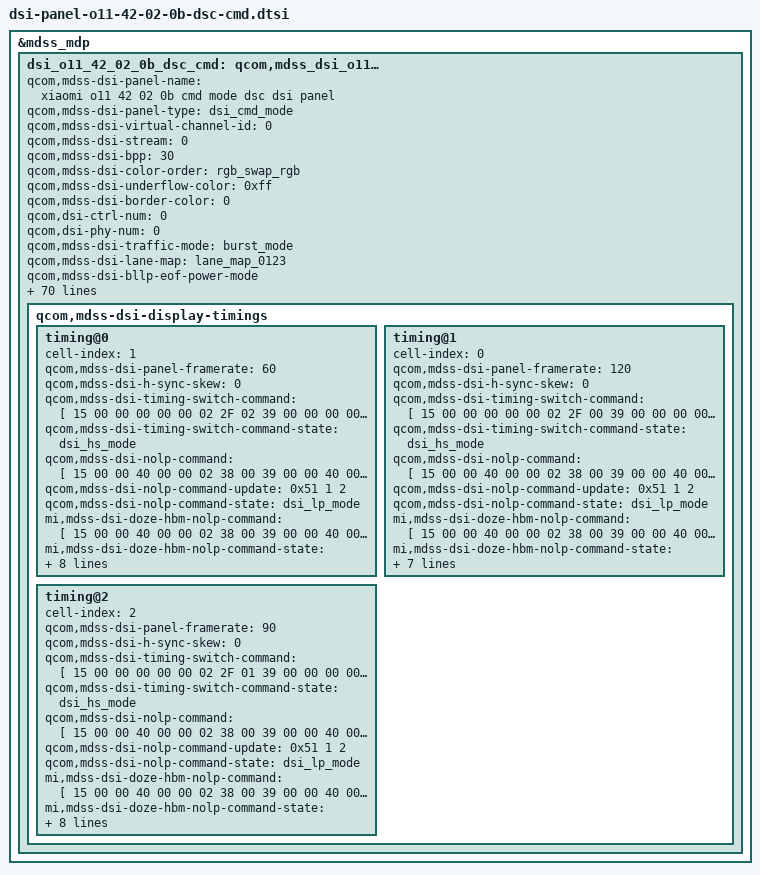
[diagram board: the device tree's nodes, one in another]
/* Panel Attention
 * 1.CCh must be 00 before 51h/26h/38h/39h/gamma change
 */
&mdss_mdp {
	dsi_o11_42_02_0b_dsc_cmd: qcom,mdss_dsi_o11_42_02_0b_dsc_cmd {
		qcom,mdss-dsi-panel-name = "xiaomi o11 42 02 0b cmd mode dsc dsi panel";
		qcom,mdss-dsi-panel-type = "dsi_cmd_mode";
		qcom,mdss-dsi-virtual-channel-id = <0>;
		qcom,mdss-dsi-stream = <0>;
		qcom,mdss-dsi-bpp = <30>;
		qcom,mdss-dsi-color-order = "rgb_swap_rgb";
		qcom,mdss-dsi-underflow-color = <0xff>;
		qcom,mdss-dsi-border-color = <0>;
		qcom,dsi-ctrl-num = <0>;
		qcom,dsi-phy-num = <0>;

		qcom,mdss-dsi-traffic-mode = "burst_mode";
		qcom,mdss-dsi-lane-map = "lane_map_0123";
		qcom,mdss-dsi-bllp-eof-power-mode;
		qcom,mdss-dsi-bllp-power-mode;
		qcom,mdss-dsi-lane-0-state;
		qcom,mdss-dsi-lane-1-state;
		qcom,mdss-dsi-lane-2-state;
		qcom,mdss-dsi-lane-3-state;
		qcom,mdss-dsi-dma-trigger = "trigger_sw";
		qcom,mdss-dsi-mdp-trigger = "none";
		qcom,mdss-dsi-reset-sequence = <1 11>, <0 1>, <1 11>;
		qcom,mdss-pan-physical-width-dimension = <695>;
		qcom,mdss-pan-physical-height-dimension = <1545>;
		qcom,mdss-dsi-te-pin-select = <1>;
		qcom,mdss-dsi-wr-mem-start = <0x2c>;
		qcom,mdss-dsi-wr-mem-continue = <0x3c>;
		qcom,mdss-dsi-te-dcs-command = <1>;
		qcom,mdss-dsi-te-check-enable;
		qcom,mdss-dsi-te-using-te-pin;
		qcom,mdss-dsi-tx-eot-append;
		qcom,mdss-dsi-lp11-init;

		qcom,mdss-dsi-bl-inverted-dbv;
		qcom,bl-update-flag = "delay_until_first_frame";

		qcom,mdss-dsi-panel-hdr-enabled;
		qcom,mdss-dsi-panel-hdr-color-primaries = <14500 15500 32000
			17000 15500 30000 8000 3000>;
		qcom,mdss-dsi-panel-peak-brightness = <32000000>;
		qcom,mdss-dsi-panel-blackness-level = <3230>;

		qcom,mdss-dsi-dma-schedule-line = <1>;
		qcom,mdss-dsi-dma-schedule-window = <50>;
		qcom,panel-supply-entries = <&dsi_panel_pwr_supply_o11>;


		qcom,spr-pack-type = "pentile";
		qcom,mdss-dsi-bl-pmic-control-type = "bl_ctrl_dcs";
		qcom,mdss-dsi-bl-min-level = <15>;
		qcom,mdss-dsi-bl-max-level = <16383>;
		qcom,bl-dsc-cmd-state = "dsi_hs_mode";
		qcom,mdss-brightness-max-level = <16383>;

		qcom,platform-reset-gpio = <&tlmm 133 0>;
		qcom,mdss-dsi-panel-vsync-delay;
		qcom,ulps-enabled;
		qcom,dsi-select-clocks = "pll_byte_clk0", "pll_dsi_clk0";
		qcom,mdss-dsi-clk-strength = <0xFF>;

		qcom,mdss-dsi-display-timings {
			/* 60 Hz */
			timing@0 {
				#include "dsi-panel-o11-42-02-0a-dsc-cmd-common.dtsi"
				cell-index = <1>;
				qcom,mdss-dsi-panel-framerate = <60>;
				qcom,mdss-dsi-h-sync-skew = <0>;
				qcom,mdss-dsi-timing-switch-command = [
					/* 60 Hz cmd_1 */
					15 00 00 00 00 00 02 2F 02
					/* EM 2pulse */
					39 00 00 00 00 00 06 F0 55 AA 52 08 00
					15 00 00 00 00 00 02 6F CC
					15 00 00 00 00 00 02 B2 01
				];
				qcom,mdss-dsi-timing-switch-command-state = "dsi_hs_mode";

				qcom,mdss-dsi-nolp-command = [
					/* AOD Mode off */
					15 00 00 40 00 00 02 38 00
					39 00 00 40 00 00 03 51 00 00
					/* 60 Hz cmd_1 */
					15 00 00 40 00 00 02 2F 02
					/* EM 2pulse */
					39 00 00 40 00 00 06 F0 55 AA 52 08 00
					15 00 00 40 00 00 02 6F CC
					15 00 00 40 00 00 02 B2 01
					/* ERR Flag enable */
					39 00 00 40 00 00 06 F0 55 AA 52 08 00
					39 00 00 40 00 00 03 BE 47 45
					15 00 00 40 00 00 02 6F 05
					15 00 00 00 00 00 02 BE 08
				];
				qcom,mdss-dsi-nolp-command-update = <0x51 1 2>;
				qcom,mdss-dsi-nolp-command-state = "dsi_lp_mode";

				mi,mdss-dsi-doze-hbm-nolp-command = [
					/* AOD Mode off */
					15 00 00 40 00 00 02 38 00
					39 00 00 40 00 00 03 51 01 9C
					/* 60 Hz cmd_1 */
					15 00 00 40 00 00 02 2F 02
					/* EM 2pulse */
					39 00 00 40 00 00 06 F0 55 AA 52 08 00
					15 00 00 40 00 00 02 6F CC
					15 00 00 40 00 00 02 B2 01
					/* ERR Flag enable */
					39 00 00 40 00 00 06 F0 55 AA 52 08 00
					39 00 00 40 00 00 03 BE 47 45
					15 00 00 40 00 00 02 6F 05
					15 00 00 00 00 00 02 BE 08
				];
				mi,mdss-dsi-doze-hbm-nolp-command-state = "dsi_lp_mode";

				mi,mdss-dsi-doze-lbm-nolp-command = [
					/* AOD Mode off */
					15 00 00 40 00 00 02 38 00
					39 00 00 40 00 00 03 51 00 23
					/* 60 Hz cmd_1 */
					15 00 00 40 00 00 02 2F 02
					/* EM 2pulse */
					39 00 00 40 00 00 06 F0 55 AA 52 08 00
					15 00 00 40 00 00 02 6F CC
					15 00 00 40 00 00 02 B2 01
					/* ERR Flag enable */
					39 00 00 40 00 00 06 F0 55 AA 52 08 00
					39 00 00 40 00 00 03 BE 47 45
					15 00 00 40 00 00 02 6F 05
					15 00 00 00 00 00 02 BE 08
				];
				mi,mdss-dsi-doze-lbm-nolp-command-state = "dsi_lp_mode";

				qcom,mdss-dsi-on-command = [
					/* 1440 */
					39 00 00 00 00 00 05 2A 00 00 05 9F
					/* 3200 */
					39 00 00 00 00 00 05 2B 00 00 0C 7F
					/* VESA Setting (DSCv1.2  2DEC  slice height=20) */
					39 00 00 00 00 00 03 90 03 43
					39 00 00 00 00 00 13 91 AB F0 00 14 D1 00 01 DE 00 A3 00 3C 05 7A 15 9A 11 50	//AP SPR
					39 00 00 00 00 00 06 F0 55 AA 52 08 03
					15 00 00 00 00 00 02 6F 09
					39 00 00 00 00 00 07 DE 10 34 25 30 14 25
					39 00 00 00 00 00 06 F0 55 AA 52 08 07
					39 00 00 00 00 00 06 B0 84 44 01 00 40
					/* 60 Hz cmd_1 */
					15 00 00 00 00 00 02 2F 02
					/* EM 2pulse */
					39 00 00 00 00 00 06 F0 55 AA 52 08 00
					15 00 00 00 00 00 02 6F CC
					15 00 00 00 00 00 02 B2 01
					39 00 00 00 00 00 03 51 00 00
					/* idle_dbv */
					15 00 00 00 00 00 02 6F 04
					39 00 00 00 00 00 03 51 0F FF
					/* BCTRL=1 */
					15 00 00 00 00 00 02 53 20
					15 00 00 00 00 00 02 35 00
					15 00 00 00 00 00 02 6F 01
					/* DC_MODE=1 */
					15 00 00 00 00 00 02 8B 00
					/* BCC OFF */
					39 00 00 00 00 00 06 F0 55 AA 52 08 08
					15 00 00 00 00 00 02 B3 00
					/* AOD pulse */
					39 00 00 00 00 00 06 F0 55 AA 52 08 01
					15 00 00 00 00 00 02 6F A2
					39 00 00 00 00 00 06 E7 FF FF FF FF FF
					15 00 00 00 00 00 02 6F 11
					15 00 00 00 00 00 02 E7 08
					/* Show Demura */
					39 00 00 00 00 00 06 F0 55 AA 52 08 00
					15 00 00 00 00 00 02 C7 33
					15 00 00 00 00 00 02 6F 31
					39 00 00 00 00 00 03 C0 00 10
					15 00 00 00 00 00 02 6F 35
					39 00 00 00 00 00 03 C0 22 40
					39 00 00 00 00 00 06 F0 55 AA 52 08 04
					15 00 00 00 00 00 02 C0 20
					/* Demura ON */
					39 00 00 40 00 00 06 F0 55 AA 52 08 04
					15 00 00 00 00 00 02 CA 01
					/* OD ON*/
					39 00 00 00 00 00 06 F0 55 AA 52 08 08
					39 00 00 00 00 00 07 E8 11 80 00 00 00 20
					15 00 00 00 00 00 02 6F 06
					39 00 00 00 00 00 18 E8 00 78 7C 7C 80 80 84 84 88 88 9C 9C 80 80 7C 7C 78 78 74 74 68 68 68
					15 00 00 00 00 00 02 6F 1D
					39 00 00 00 00 00 18 E8 00 88 90 90 94 94 9C 9C A0 A0 B8 B8 90 90 8C 8C 88 88 84 84 74 74 74
					15 00 00 00 00 00 02 6F 34
					39 00 00 00 00 00 18 E8 00 E8 E8 E8 E8 E8 E8 E8 E8 E8 F0 F0 AC AC AC AC A8 A8 A8 A8 90 90 90
					39 00 00 00 00 00 06 F0 55 AA 52 08 08
					39 00 00 00 00 00 05 E0 01 01 01 01
					15 00 00 00 00 00 02 6F 06
					39 00 00 00 00 00 0E E0 80 00 21 32 43 54 65 76 87 98 99 99 99
					39 00 00 00 00 00 33 E1 00 00 00 00 00 00 01 01 01 02 02 03 03 05 00 00 00 00 00 00 00 00 00 03 03 05 08 0A 00 00 00 00 00 00 01 01 02 04 04 05 08 0A 00 00 00 00 00 00 00 00
					15 00 00 00 00 00 02 6F 32
					39 00 00 00 00 00 33 E1 03 04 06 07 0B 0C 00 00 00 00 00 00 01 01 04 07 09 0A 0C 0E 00 00 01 01 02 02 02 03 04 06 07 09 0A 0B 00 00 01 01 02 02 02 03 06 07 09 0A 0C 0D 00 00
					15 00 00 00 00 00 02 6F 64
					39 00 00 00 00 00 1B E1 00 00 00 01 02 02 03 05 08 0C 0D 0E 00 00 00 00 01 02 02 03 05 06 09 0B 0F 11
					39 00 00 00 00 00 33 E2 01 02 02 03 04 04 04 05 0A 0A 0E 14 1A 1A 00 00 00 00 01 02 03 04 06 06 0C 10 12 11 00 00 00 00 02 04 06 08 0A 0A 0A 0E 10 11 00 00 00 00 02 04 05 07
					15 00 00 00 00 00 02 6F 32
					39 00 00 00 00 00 33 E2 07 09 0B 0C 0F 12 00 00 00 00 02 04 05 07 07 08 0B 0D 10 11 00 00 00 00 02 03 04 06 06 08 0A 0C 0D 0F 00 00 00 00 01 02 04 05 07 09 0B 0C 0F 11 00 01
					15 00 00 00 00 00 02 6F 64
					39 00 00 00 00 00 1B E2 02 02 02 03 04 04 07 08 09 0D 0E 12 00 00 00 00 01 02 03 04 06 08 09 0B 10 12
					39 00 00 00 00 00 33 E3 00 00 00 00 00 00 00 00 00 00 06 07 08 0A 00 00 00 00 00 00 00 00 00 00 05 0A 0F 0F 00 00 00 00 00 00 00 00 00 04 04 06 0E 10 00 00 00 00 00 01 02 02
					15 00 00 00 00 00 02 6F 32
					39 00 00 00 00 00 33 E3 02 06 08 0C 0D 0F 00 00 00 00 00 01 02 02 05 06 0A 0B 0E 11 00 00 00 00 01 02 03 04 04 07 08 0A 0D 0F 00 00 00 00 01 02 02 03 06 08 09 0B 0E 11 00 00
					15 00 00 00 00 00 02 6F 64
					39 00 00 00 00 00 1B E3 01 01 02 02 03 04 05 07 0A 0C 0F 11 00 00 00 00 01 02 02 03 06 07 0A 0D 0F 12
					39 00 00 00 00 00 1C EA 00 00 00 00 00 00 00 00 00 00 00 00 00 00 00 00 00 00 00 00 00 00 00 00 00 00 00
					39 00 00 00 00 00 0A E4 00 00 00 00 00 00 00 00 00
					39 00 00 00 00 00 0A E5 00 00 00 00 00 00 00 00 00
					39 00 00 00 00 00 0A E6 00 00 00 00 00 00 00 00 00
					39 00 00 40 00 00 06 F0 55 AA 52 08 08
					15 00 00 40 00 00 02 E8 11
					15 00 00 00 00 00 02 E0 01
					/* DBV Remapping */
					39 00 00 00 00 00 06 F0 55 AA 52 08 09
					15 00 00 00 00 00 02 BC 01
					15 00 00 00 00 00 02 6F 25
					39 00 00 00 00 00 13 BC 01 9B 01 9B 01 9B 04 18 05 AC 06 F7 09 FF 0B FF 0D FF
					15 00 00 00 00 00 02 6F 37
					39 00 00 00 00 00 13 BC 11 54 12 A9 13 FE 1D EF 24 9F 2A B9 33 FD 37 FE 3B FE
					15 00 00 00 00 00 02 6F 49
					39 00 00 00 00 00 13 BC 01 9B 01 9B 01 9B 04 18 05 AC 06 F7 09 FF 0B FF 0D FF
					15 00 00 00 00 00 02 6F 5B
					39 00 00 00 00 00 13 BC 11 54 12 A9 13 FE 1D EF 24 9F 2A B9 33 FD 37 FE 3B FE
					/* ESD ERR Flag */
					39 00 00 00 00 00 06 F0 55 AA 52 08 00
					39 00 00 00 00 00 03 BE 47 45
					15 00 00 00 00 00 02 6F 05
					15 00 00 00 00 00 02 BE 08
					39 00 00 00 00 00 06 F0 55 AA 52 08 00
					15 00 00 00 00 00 02 6F 18
					15 00 00 00 00 00 02 B2 41
					/*  ESD error config */
					39 00 00 00 00 00 06 F0 55 AA 52 08 03
					39 00 00 00 00 00 04 C8 01 FF FB
					39 00 00 00 00 00 05 FF AA 55 A5 80
					15 00 00 00 00 00 02 6F 22
					15 00 00 00 00 00 02 FE 06
					/* APL Data scaling */
					39 00 00 00 00 00 06 F0 55 AA 52 08 00
					15 00 00 00 00 00 02 6F 78
					39 00 00 00 00 00 18 B0 11 00 2A 00 C2 01 DA 03 7C 05 B1 08 80 0B EE 0F FF 05 55 05 56 05 55
					15 00 00 00 00 00 02 6F 6F
					39 00 00 00 00 00 07 B0 02 D0 05 A0 02 D0
					39 00 00 00 00 00 06 F0 55 AA 52 08 08
					39 00 00 00 00 00 17 C1 8C FF CC FF FF CC FF FF CC FF FF EC FF 7F EE 7F 7F FF 7F FF 0E 7F
					15 00 00 00 00 00 02 6F 20
					39 00 00 00 00 00 04 C1 4F 00 FF
					15 00 00 00 00 00 02 6F 23
					39 00 00 00 00 00 15 C1 0C FF CC FF FF CC FF FF CC FF FF EC FF 7F EE 7F 7F CF 7F 0A
					/* Round ON */
					39 00 00 00 00 00 06 F0 55 AA 52 08 07
					15 00 00 00 00 00 02 C0 87
					/* OSC_Trim_On */
					39 00 00 00 00 00 06 F0 55 AA 52 08 01
					15 00 00 00 00 00 02 6F 2F
					15 00 00 00 00 00 02 C3 77
					/* OSC=125.2MHz, 1200Mbps */
					15 00 00 00 00 00 02 6F 00
					15 00 00 00 00 00 02 C3 DD
					15 00 00 00 00 00 02 6F 30
					15 00 00 00 00 00 02 C3 C0
					15 00 00 00 00 00 02 6F 0B
					39 00 00 00 00 00 04 C3 3F 3A 2F
					15 00 00 00 00 00 02 6F 11
					39 00 00 00 00 00 04 C3 3F 3A 2F
					15 00 00 00 00 00 02 6F 17
					39 00 00 00 00 00 04 C3 3F 3A 2F
					15 00 00 00 00 00 02 6F 1D
					39 00 00 00 00 00 04 C3 3F 3A 2F
					15 00 00 00 00 00 02 6F 23
					39 00 00 00 00 00 04 C3 3F 3A 2F
					15 00 00 00 00 00 02 6F 0E
					39 00 00 00 00 00 04 C3 3F 62 DE
					15 00 00 00 00 00 02 6F 14
					39 00 00 00 00 00 04 C3 3F 62 DE
					15 00 00 00 00 00 02 6F 1A
					39 00 00 00 00 00 04 C3 3F 62 DE
					15 00 00 00 00 00 02 6F 20
					39 00 00 00 00 00 04 C3 3F 62 DE
					15 00 00 00 00 00 02 6F 26
					39 00 00 00 00 00 04 C3 3F 62 DE
					15 00 00 00 00 00 02 6F 29
					39 00 00 00 00 00 04 C3 11 11 01
					15 00 00 00 00 00 02 6F 2C
					39 00 00 00 00 00 04 C3 00 00 00
					15 00 00 00 00 00 02 6F 31
					39 00 00 00 00 00 03 C3 AA 02
					15 00 00 00 00 00 02 6F 33
					39 00 00 00 00 00 03 C3 AA 02
					15 00 00 00 00 00 02 6F 04
					15 00 00 00 00 00 02 C3 E3
					15 00 00 00 00 00 02 6F 09
					15 00 00 00 00 00 02 C3 E4
					15 00 00 00 00 00 02 6F 01
					15 00 00 00 00 00 02 C3 29
					15 00 00 00 00 00 02 6F 06
					15 00 00 00 00 00 02 C3 29
					15 00 00 00 00 00 02 6F 02
					39 00 00 00 00 00 03 C3 02 70
					15 00 00 00 00 00 02 6F 08
					15 00 00 00 00 00 02 C3 70
					39 00 00 00 00 00 06 F0 55 AA 52 08 01
					15 00 00 00 00 00 02 EA 11
					15 00 00 00 00 00 02 6F 07
					39 00 00 00 00 00 03 EA 01 39
					15 00 00 00 00 00 02 6F 0B
					15 00 00 00 00 00 02 EA 11
					15 00 00 00 00 00 02 6F 12
					39 00 00 00 00 00 03 EA 01 AC
					15 00 00 00 00 00 02 6F 1A
					39 00 00 00 00 00 03 EA 01 39
					15 00 00 00 00 00 02 6F 1C
					39 00 00 00 00 00 03 EA 01 AC
					15 00 00 00 00 00 02 6F 04
					15 00 00 00 00 00 02 C3 EA
					15 00 00 00 00 00 02 6F 09
					15 00 00 00 00 00 02 C3 EA
					/* Sleep Out */
					05 00 00 00 78 00 02 11 00
					/* Display On */
					05 00 00 00 00 00 02 29 00
				];
				qcom,mdss-dsi-on-command-state = "dsi_lp_mode";
			};

			/* 120 Hz */
			timing@1 {
				#include "dsi-panel-o11-42-02-0a-dsc-cmd-common.dtsi"
				cell-index = <0>;
				qcom,mdss-dsi-panel-framerate = <120>;
				qcom,mdss-dsi-h-sync-skew = <0>;
				qcom,mdss-dsi-timing-switch-command = [
					/* 120 Hz cmd_1 */
					15 00 00 00 00 00 02 2F 00
					/* EM 1pulse */
					39 00 00 00 00 00 06 F0 55 AA 52 08 00
					15 00 00 00 00 00 02 6F CC
					15 00 00 00 00 00 02 B2 00
				];
				qcom,mdss-dsi-timing-switch-command-state = "dsi_hs_mode";

				qcom,mdss-dsi-nolp-command = [
					/* AOD Mode off */
					15 00 00 40 00 00 02 38 00
					39 00 00 40 00 00 03 51 00 00
					/* 120 Hz cmd_1 */
					15 00 00 40 00 00 02 2F 00
					/* EM 1pulse */
					39 00 00 40 00 00 06 F0 55 AA 52 08 00
					15 00 00 40 00 00 02 6F CC
					15 00 00 40 00 00 02 B2 00
					/* ERR Flag enable */
					39 00 00 40 00 00 06 F0 55 AA 52 08 00
					39 00 00 40 00 00 03 BE 47 45
					15 00 00 40 00 00 02 6F 05
					15 00 00 00 00 00 02 BE 08
				];
				qcom,mdss-dsi-nolp-command-update = <0x51 1 2>;
				qcom,mdss-dsi-nolp-command-state = "dsi_lp_mode";

				mi,mdss-dsi-doze-hbm-nolp-command = [
					/* AOD Mode off */
					15 00 00 40 00 00 02 38 00
					39 00 00 40 00 00 03 51 01 9C
					/* 120 Hz cmd_1 */
					15 00 00 40 00 00 02 2F 00
					/* EM 1pulse */
					39 00 00 40 00 00 06 F0 55 AA 52 08 00
					15 00 00 40 00 00 02 6F CC
					15 00 00 40 00 00 02 B2 00
					/* ERR Flag enable */
					39 00 00 40 00 00 06 F0 55 AA 52 08 00
					39 00 00 40 00 00 03 BE 47 45
					15 00 00 40 00 00 02 6F 05
					15 00 00 00 00 00 02 BE 08
				];
				mi,mdss-dsi-doze-hbm-nolp-command-state = "dsi_lp_mode";

				mi,mdss-dsi-doze-lbm-nolp-command = [
					/* AOD Mode off */
					15 00 00 40 00 00 02 38 00
					39 00 00 40 00 00 03 51 00 23
					/* 120 Hz cmd_1 */
					15 00 00 40 00 00 02 2F 00
					/* EM 1pulse */
					39 00 00 40 00 00 06 F0 55 AA 52 08 00
					15 00 00 40 00 00 02 6F CC
					15 00 00 40 00 00 02 B2 00
					/* ERR Flag enable */
					39 00 00 40 00 00 06 F0 55 AA 52 08 00
					39 00 00 40 00 00 03 BE 47 45
					15 00 00 40 00 00 02 6F 05
					15 00 00 00 00 00 02 BE 08
				];
				mi,mdss-dsi-doze-lbm-nolp-command-state = "dsi_lp_mode";

				qcom,mdss-dsi-on-command = [
					/* 1440 */
					39 00 00 00 00 00 05 2A 00 00 05 9F
					/* 3200 */
					39 00 00 00 00 00 05 2B 00 00 0C 7F
					/* VESA Setting (DSCv1.2  2DEC  slice height=20) */
					39 00 00 00 00 00 03 90 03 43
					39 00 00 00 00 00 13 91 AB F0 00 14 D1 00 01 DE 00 A3 00 3C 05 7A 15 9A 11 50	//AP SPR
					39 00 00 00 00 00 06 F0 55 AA 52 08 03
					15 00 00 00 00 00 02 6F 09
					39 00 00 00 00 00 07 DE 10 34 25 30 14 25
					39 00 00 00 00 00 06 F0 55 AA 52 08 07
					39 00 00 00 00 00 06 B0 84 44 01 00 40
					/* 120 Hz cmd_1 */
					15 00 00 00 00 00 02 2F 00
					/* EM 1pulse */
					39 00 00 00 00 00 06 F0 55 AA 52 08 00
					15 00 00 00 00 00 02 6F CC
					15 00 00 00 00 00 02 B2 00
					39 00 00 00 00 00 03 51 00 00
					/* idle_dbv */
					15 00 00 00 00 00 02 6F 04
					39 00 00 00 00 00 03 51 0F FF
					/* BCTRL=1 */
					15 00 00 00 00 00 02 53 20
					15 00 00 00 00 00 02 35 00
					15 00 00 00 00 00 02 6F 01
					/* DC_MODE=1 */
					15 00 00 00 00 00 02 8B 00
					/* BCC OFF */
					39 00 00 00 00 00 06 F0 55 AA 52 08 08
					15 00 00 00 00 00 02 B3 00
					/* AOD pulse */
					39 00 00 00 00 00 06 F0 55 AA 52 08 01
					15 00 00 00 00 00 02 6F A2
					39 00 00 00 00 00 06 E7 FF FF FF FF FF
					15 00 00 00 00 00 02 6F 11
					15 00 00 00 00 00 02 E7 08
					/* Show Demura */
					39 00 00 00 00 00 06 F0 55 AA 52 08 00
					15 00 00 00 00 00 02 C7 33
					15 00 00 00 00 00 02 6F 31
					39 00 00 00 00 00 03 C0 00 10
					15 00 00 00 00 00 02 6F 35
					39 00 00 00 00 00 03 C0 22 40
					39 00 00 00 00 00 06 F0 55 AA 52 08 04
					15 00 00 00 00 00 02 C0 20
					/* Demura ON */
					39 00 00 40 00 00 06 F0 55 AA 52 08 04
					15 00 00 00 00 00 02 CA 01
					/* OD ON*/
					39 00 00 00 00 00 06 F0 55 AA 52 08 08
					39 00 00 00 00 00 07 E8 11 80 00 00 00 20
					15 00 00 00 00 00 02 6F 06
					39 00 00 00 00 00 18 E8 00 78 7C 7C 80 80 84 84 88 88 9C 9C 80 80 7C 7C 78 78 74 74 68 68 68
					15 00 00 00 00 00 02 6F 1D
					39 00 00 00 00 00 18 E8 00 88 90 90 94 94 9C 9C A0 A0 B8 B8 90 90 8C 8C 88 88 84 84 74 74 74
					15 00 00 00 00 00 02 6F 34
					39 00 00 00 00 00 18 E8 00 E8 E8 E8 E8 E8 E8 E8 E8 E8 F0 F0 AC AC AC AC A8 A8 A8 A8 90 90 90
					39 00 00 00 00 00 06 F0 55 AA 52 08 08
					39 00 00 00 00 00 05 E0 01 01 01 01
					15 00 00 00 00 00 02 6F 06
					39 00 00 00 00 00 0E E0 80 00 21 32 43 54 65 76 87 98 99 99 99
					39 00 00 00 00 00 33 E1 00 00 00 00 00 00 01 01 01 02 02 03 03 05 00 00 00 00 00 00 00 00 00 03 03 05 08 0A 00 00 00 00 00 00 01 01 02 04 04 05 08 0A 00 00 00 00 00 00 00 00
					15 00 00 00 00 00 02 6F 32
					39 00 00 00 00 00 33 E1 03 04 06 07 0B 0C 00 00 00 00 00 00 01 01 04 07 09 0A 0C 0E 00 00 01 01 02 02 02 03 04 06 07 09 0A 0B 00 00 01 01 02 02 02 03 06 07 09 0A 0C 0D 00 00
					15 00 00 00 00 00 02 6F 64
					39 00 00 00 00 00 1B E1 00 00 00 01 02 02 03 05 08 0C 0D 0E 00 00 00 00 01 02 02 03 05 06 09 0B 0F 11
					39 00 00 00 00 00 33 E2 01 02 02 03 04 04 04 05 0A 0A 0E 14 1A 1A 00 00 00 00 01 02 03 04 06 06 0C 10 12 11 00 00 00 00 02 04 06 08 0A 0A 0A 0E 10 11 00 00 00 00 02 04 05 07
					15 00 00 00 00 00 02 6F 32
					39 00 00 00 00 00 33 E2 07 09 0B 0C 0F 12 00 00 00 00 02 04 05 07 07 08 0B 0D 10 11 00 00 00 00 02 03 04 06 06 08 0A 0C 0D 0F 00 00 00 00 01 02 04 05 07 09 0B 0C 0F 11 00 01
					15 00 00 00 00 00 02 6F 64
					39 00 00 00 00 00 1B E2 02 02 02 03 04 04 07 08 09 0D 0E 12 00 00 00 00 01 02 03 04 06 08 09 0B 10 12
					39 00 00 00 00 00 33 E3 00 00 00 00 00 00 00 00 00 00 06 07 08 0A 00 00 00 00 00 00 00 00 00 00 05 0A 0F 0F 00 00 00 00 00 00 00 00 00 04 04 06 0E 10 00 00 00 00 00 01 02 02
					15 00 00 00 00 00 02 6F 32
					39 00 00 00 00 00 33 E3 02 06 08 0C 0D 0F 00 00 00 00 00 01 02 02 05 06 0A 0B 0E 11 00 00 00 00 01 02 03 04 04 07 08 0A 0D 0F 00 00 00 00 01 02 02 03 06 08 09 0B 0E 11 00 00
					15 00 00 00 00 00 02 6F 64
					39 00 00 00 00 00 1B E3 01 01 02 02 03 04 05 07 0A 0C 0F 11 00 00 00 00 01 02 02 03 06 07 0A 0D 0F 12
					39 00 00 00 00 00 1C EA 00 00 00 00 00 00 00 00 00 00 00 00 00 00 00 00 00 00 00 00 00 00 00 00 00 00 00
					39 00 00 00 00 00 0A E4 00 00 00 00 00 00 00 00 00
					39 00 00 00 00 00 0A E5 00 00 00 00 00 00 00 00 00
					39 00 00 00 00 00 0A E6 00 00 00 00 00 00 00 00 00
					39 00 00 40 00 00 06 F0 55 AA 52 08 08
					15 00 00 40 00 00 02 E8 11
					15 00 00 00 00 00 02 E0 01
					/* DBV Remapping */
					39 00 00 00 00 00 06 F0 55 AA 52 08 09
					15 00 00 00 00 00 02 BC 01
					15 00 00 00 00 00 02 6F 25
					39 00 00 00 00 00 13 BC 01 9B 01 9B 01 9B 04 18 05 AC 06 F7 09 FF 0B FF 0D FF
					15 00 00 00 00 00 02 6F 37
					39 00 00 00 00 00 13 BC 11 54 12 A9 13 FE 1D EF 24 9F 2A B9 33 FD 37 FE 3B FE
					15 00 00 00 00 00 02 6F 49
					39 00 00 00 00 00 13 BC 01 9B 01 9B 01 9B 04 18 05 AC 06 F7 09 FF 0B FF 0D FF
					15 00 00 00 00 00 02 6F 5B
					39 00 00 00 00 00 13 BC 11 54 12 A9 13 FE 1D EF 24 9F 2A B9 33 FD 37 FE 3B FE
					/* ESD ERR Flag */
					39 00 00 00 00 00 06 F0 55 AA 52 08 00
					39 00 00 00 00 00 03 BE 47 45
					15 00 00 00 00 00 02 6F 05
					15 00 00 00 00 00 02 BE 08
					39 00 00 00 00 00 06 F0 55 AA 52 08 00
					15 00 00 00 00 00 02 6F 18
					15 00 00 00 00 00 02 B2 41
					/*  ESD error config */
					39 00 00 00 00 00 06 F0 55 AA 52 08 03
					39 00 00 00 00 00 04 C8 01 FF FB
					39 00 00 00 00 00 05 FF AA 55 A5 80
					15 00 00 00 00 00 02 6F 22
					15 00 00 00 00 00 02 FE 06
					/* APL Data scaling */
					39 00 00 00 00 00 06 F0 55 AA 52 08 00
					15 00 00 00 00 00 02 6F 78
					39 00 00 00 00 00 18 B0 11 00 2A 00 C2 01 DA 03 7C 05 B1 08 80 0B EE 0F FF 05 55 05 56 05 55
					15 00 00 00 00 00 02 6F 6F
					39 00 00 00 00 00 07 B0 02 D0 05 A0 02 D0
					39 00 00 00 00 00 06 F0 55 AA 52 08 08
					39 00 00 00 00 00 17 C1 8C FF CC FF FF CC FF FF CC FF FF EC FF 7F EE 7F 7F FF 7F FF 0E 7F
					15 00 00 00 00 00 02 6F 20
					39 00 00 00 00 00 04 C1 4F 00 FF
					15 00 00 00 00 00 02 6F 23
					39 00 00 00 00 00 15 C1 0C FF CC FF FF CC FF FF CC FF FF EC FF 7F EE 7F 7F CF 7F 0A
					/* Round ON */
					39 00 00 00 00 00 06 F0 55 AA 52 08 07
					15 00 00 00 00 00 02 C0 87
					/* OSC_Trim_On */
					39 00 00 00 00 00 06 F0 55 AA 52 08 01
					15 00 00 00 00 00 02 6F 2F
					15 00 00 00 00 00 02 C3 77
					/* OSC=125.2MHz, 1200Mbps */
					15 00 00 00 00 00 02 6F 00
					15 00 00 00 00 00 02 C3 DD
					15 00 00 00 00 00 02 6F 30
					15 00 00 00 00 00 02 C3 C0
					15 00 00 00 00 00 02 6F 0B
					39 00 00 00 00 00 04 C3 3F 3A 2F
					15 00 00 00 00 00 02 6F 11
					39 00 00 00 00 00 04 C3 3F 3A 2F
					15 00 00 00 00 00 02 6F 17
					39 00 00 00 00 00 04 C3 3F 3A 2F
					15 00 00 00 00 00 02 6F 1D
					39 00 00 00 00 00 04 C3 3F 3A 2F
					15 00 00 00 00 00 02 6F 23
					39 00 00 00 00 00 04 C3 3F 3A 2F
					15 00 00 00 00 00 02 6F 0E
					39 00 00 00 00 00 04 C3 3F 62 DE
					15 00 00 00 00 00 02 6F 14
					39 00 00 00 00 00 04 C3 3F 62 DE
					15 00 00 00 00 00 02 6F 1A
					39 00 00 00 00 00 04 C3 3F 62 DE
					15 00 00 00 00 00 02 6F 20
					39 00 00 00 00 00 04 C3 3F 62 DE
					15 00 00 00 00 00 02 6F 26
					39 00 00 00 00 00 04 C3 3F 62 DE
					15 00 00 00 00 00 02 6F 29
					39 00 00 00 00 00 04 C3 11 11 01
					15 00 00 00 00 00 02 6F 2C
					39 00 00 00 00 00 04 C3 00 00 00
					15 00 00 00 00 00 02 6F 31
					39 00 00 00 00 00 03 C3 AA 02
					15 00 00 00 00 00 02 6F 33
					39 00 00 00 00 00 03 C3 AA 02
					15 00 00 00 00 00 02 6F 04
					15 00 00 00 00 00 02 C3 E3
					15 00 00 00 00 00 02 6F 09
					15 00 00 00 00 00 02 C3 E4
					15 00 00 00 00 00 02 6F 01
					15 00 00 00 00 00 02 C3 29
					15 00 00 00 00 00 02 6F 06
					15 00 00 00 00 00 02 C3 29
					15 00 00 00 00 00 02 6F 02
					39 00 00 00 00 00 03 C3 02 70
					15 00 00 00 00 00 02 6F 08
					15 00 00 00 00 00 02 C3 70
					39 00 00 00 00 00 06 F0 55 AA 52 08 01
					15 00 00 00 00 00 02 EA 11
					15 00 00 00 00 00 02 6F 07
					39 00 00 00 00 00 03 EA 01 39
					15 00 00 00 00 00 02 6F 0B
					15 00 00 00 00 00 02 EA 11
					15 00 00 00 00 00 02 6F 12
					39 00 00 00 00 00 03 EA 01 AC
					15 00 00 00 00 00 02 6F 1A
					39 00 00 00 00 00 03 EA 01 39
					15 00 00 00 00 00 02 6F 1C
					39 00 00 00 00 00 03 EA 01 AC
					15 00 00 00 00 00 02 6F 04
					15 00 00 00 00 00 02 C3 EA
					15 00 00 00 00 00 02 6F 09
					15 00 00 00 00 00 02 C3 EA
					/* Sleep Out */
					05 00 00 00 78 00 02 11 00
					/* Display On */
					05 00 00 00 00 00 02 29 00
				];
			};

			/* 90 Hz */
			timing@2 {
				#include "dsi-panel-o11-42-02-0a-dsc-cmd-common.dtsi"
				cell-index = <2>;
				qcom,mdss-dsi-panel-framerate = <90>;
				qcom,mdss-dsi-h-sync-skew = <0>;
				qcom,mdss-dsi-timing-switch-command = [
					/* 90 Hz cmd_1 */
					15 00 00 00 00 00 02 2F 01
					/* EM 1pulse */
					39 00 00 00 00 00 06 F0 55 AA 52 08 00
					15 00 00 00 00 00 02 6F CC
					15 00 00 00 00 00 02 B2 00
				];
				qcom,mdss-dsi-timing-switch-command-state = "dsi_hs_mode";

				qcom,mdss-dsi-nolp-command = [
					/* AOD Mode off */
					15 00 00 40 00 00 02 38 00
					39 00 00 40 00 00 03 51 00 00
					/* 90 Hz cmd_1 */
					15 00 00 40 00 00 02 2F 01
					/* EM 1pulse */
					39 00 00 40 00 00 06 F0 55 AA 52 08 00
					15 00 00 40 00 00 02 6F CC
					15 00 00 40 00 00 02 B2 00
					/* ERR Flag enable */
					39 00 00 40 00 00 06 F0 55 AA 52 08 00
					39 00 00 40 00 00 03 BE 47 45
					15 00 00 40 00 00 02 6F 05
					15 00 00 00 00 00 02 BE 08
				];
				qcom,mdss-dsi-nolp-command-update = <0x51 1 2>;
				qcom,mdss-dsi-nolp-command-state = "dsi_lp_mode";

				mi,mdss-dsi-doze-hbm-nolp-command = [
					/* AOD Mode off */
					15 00 00 40 00 00 02 38 00
					39 00 00 40 00 00 03 51 01 9C
					/* 90 Hz cmd_1 */
					15 00 00 40 00 00 02 2F 01
					/* EM 1pulse */
					39 00 00 40 00 00 06 F0 55 AA 52 08 00
					15 00 00 40 00 00 02 6F CC
					15 00 00 40 00 00 02 B2 00
					/* ERR Flag enable */
					39 00 00 40 00 00 06 F0 55 AA 52 08 00
					39 00 00 40 00 00 03 BE 47 45
					15 00 00 40 00 00 02 6F 05
					15 00 00 00 00 00 02 BE 08
				];
				mi,mdss-dsi-doze-hbm-nolp-command-state = "dsi_lp_mode";

				mi,mdss-dsi-doze-lbm-nolp-command = [
					/* AOD Mode off */
					15 00 00 40 00 00 02 38 00
					39 00 00 40 00 00 03 51 00 23
					/* 90 Hz cmd_1 */
					15 00 00 40 00 00 02 2F 01
					/* EM 1pulse */
					39 00 00 40 00 00 06 F0 55 AA 52 08 00
					15 00 00 40 00 00 02 6F CC
					15 00 00 40 00 00 02 B2 00
					/* ERR Flag enable */
					39 00 00 40 00 00 06 F0 55 AA 52 08 00
					39 00 00 40 00 00 03 BE 47 45
					15 00 00 40 00 00 02 6F 05
					15 00 00 00 00 00 02 BE 08
				];
				mi,mdss-dsi-doze-lbm-nolp-command-state = "dsi_lp_mode";

				qcom,mdss-dsi-on-command = [
					/* 1440 */
					39 00 00 00 00 00 05 2A 00 00 05 9F
					/* 3200 */
					39 00 00 00 00 00 05 2B 00 00 0C 7F
					/* VESA Setting (DSCv1.2  2DEC  slice height=20) */
					39 00 00 00 00 00 03 90 03 43
					39 00 00 00 00 00 13 91 AB F0 00 14 D1 00 01 DE 00 A3 00 3C 05 7A 15 9A 11 50	//AP SPR
					39 00 00 00 00 00 06 F0 55 AA 52 08 03
					15 00 00 00 00 00 02 6F 09
					39 00 00 00 00 00 07 DE 10 34 25 30 14 25
					39 00 00 00 00 00 06 F0 55 AA 52 08 07
					39 00 00 00 00 00 06 B0 84 44 01 00 40
					/* 90 Hz cmd_1 */
					15 00 00 00 00 00 02 2F 01
					/* EM 1pulse */
					39 00 00 00 00 00 06 F0 55 AA 52 08 00
					15 00 00 00 00 00 02 6F CC
					15 00 00 00 00 00 02 B2 00
					39 00 00 00 00 00 03 51 00 00
					/* idle_dbv */
					15 00 00 00 00 00 02 6F 04
					39 00 00 00 00 00 03 51 0F FF
					/* BCTRL=1 */
					15 00 00 00 00 00 02 53 20
					15 00 00 00 00 00 02 35 00
					15 00 00 00 00 00 02 6F 01
					/* DC_MODE=1 */
					15 00 00 00 00 00 02 8B 00
					/* BCC OFF */
					39 00 00 00 00 00 06 F0 55 AA 52 08 08
					15 00 00 00 00 00 02 B3 00
					/* AOD pulse */
					39 00 00 00 00 00 06 F0 55 AA 52 08 01
					15 00 00 00 00 00 02 6F A2
					39 00 00 00 00 00 06 E7 FF FF FF FF FF
					15 00 00 00 00 00 02 6F 11
					15 00 00 00 00 00 02 E7 08
					/* Show Demura */
					39 00 00 00 00 00 06 F0 55 AA 52 08 00
					15 00 00 00 00 00 02 C7 33
					15 00 00 00 00 00 02 6F 31
					39 00 00 00 00 00 03 C0 00 10
					15 00 00 00 00 00 02 6F 35
					39 00 00 00 00 00 03 C0 22 40
					39 00 00 00 00 00 06 F0 55 AA 52 08 04
					15 00 00 00 00 00 02 C0 20
					/* Demura ON */
					39 00 00 40 00 00 06 F0 55 AA 52 08 04
					15 00 00 00 00 00 02 CA 01
					/* OD ON*/
					39 00 00 00 00 00 06 F0 55 AA 52 08 08
					39 00 00 00 00 00 07 E8 11 80 00 00 00 20
					15 00 00 00 00 00 02 6F 06
					39 00 00 00 00 00 18 E8 00 78 7C 7C 80 80 84 84 88 88 9C 9C 80 80 7C 7C 78 78 74 74 68 68 68
					15 00 00 00 00 00 02 6F 1D
					39 00 00 00 00 00 18 E8 00 88 90 90 94 94 9C 9C A0 A0 B8 B8 90 90 8C 8C 88 88 84 84 74 74 74
					15 00 00 00 00 00 02 6F 34
					39 00 00 00 00 00 18 E8 00 E8 E8 E8 E8 E8 E8 E8 E8 E8 F0 F0 AC AC AC AC A8 A8 A8 A8 90 90 90
					39 00 00 00 00 00 06 F0 55 AA 52 08 08
					39 00 00 00 00 00 05 E0 01 01 01 01
					15 00 00 00 00 00 02 6F 06
					39 00 00 00 00 00 0E E0 80 00 21 32 43 54 65 76 87 98 99 99 99
					39 00 00 00 00 00 33 E1 00 00 00 00 00 00 01 01 01 02 02 03 03 05 00 00 00 00 00 00 00 00 00 03 03 05 08 0A 00 00 00 00 00 00 01 01 02 04 04 05 08 0A 00 00 00 00 00 00 00 00
					15 00 00 00 00 00 02 6F 32
					39 00 00 00 00 00 33 E1 03 04 06 07 0B 0C 00 00 00 00 00 00 01 01 04 07 09 0A 0C 0E 00 00 01 01 02 02 02 03 04 06 07 09 0A 0B 00 00 01 01 02 02 02 03 06 07 09 0A 0C 0D 00 00
					15 00 00 00 00 00 02 6F 64
					39 00 00 00 00 00 1B E1 00 00 00 01 02 02 03 05 08 0C 0D 0E 00 00 00 00 01 02 02 03 05 06 09 0B 0F 11
					39 00 00 00 00 00 33 E2 01 02 02 03 04 04 04 05 0A 0A 0E 14 1A 1A 00 00 00 00 01 02 03 04 06 06 0C 10 12 11 00 00 00 00 02 04 06 08 0A 0A 0A 0E 10 11 00 00 00 00 02 04 05 07
					15 00 00 00 00 00 02 6F 32
					39 00 00 00 00 00 33 E2 07 09 0B 0C 0F 12 00 00 00 00 02 04 05 07 07 08 0B 0D 10 11 00 00 00 00 02 03 04 06 06 08 0A 0C 0D 0F 00 00 00 00 01 02 04 05 07 09 0B 0C 0F 11 00 01
					15 00 00 00 00 00 02 6F 64
					39 00 00 00 00 00 1B E2 02 02 02 03 04 04 07 08 09 0D 0E 12 00 00 00 00 01 02 03 04 06 08 09 0B 10 12
					39 00 00 00 00 00 33 E3 00 00 00 00 00 00 00 00 00 00 06 07 08 0A 00 00 00 00 00 00 00 00 00 00 05 0A 0F 0F 00 00 00 00 00 00 00 00 00 04 04 06 0E 10 00 00 00 00 00 01 02 02
					15 00 00 00 00 00 02 6F 32
					39 00 00 00 00 00 33 E3 02 06 08 0C 0D 0F 00 00 00 00 00 01 02 02 05 06 0A 0B 0E 11 00 00 00 00 01 02 03 04 04 07 08 0A 0D 0F 00 00 00 00 01 02 02 03 06 08 09 0B 0E 11 00 00
					15 00 00 00 00 00 02 6F 64
					39 00 00 00 00 00 1B E3 01 01 02 02 03 04 05 07 0A 0C 0F 11 00 00 00 00 01 02 02 03 06 07 0A 0D 0F 12
					39 00 00 00 00 00 1C EA 00 00 00 00 00 00 00 00 00 00 00 00 00 00 00 00 00 00 00 00 00 00 00 00 00 00 00
					39 00 00 00 00 00 0A E4 00 00 00 00 00 00 00 00 00
					39 00 00 00 00 00 0A E5 00 00 00 00 00 00 00 00 00
					39 00 00 00 00 00 0A E6 00 00 00 00 00 00 00 00 00
					39 00 00 40 00 00 06 F0 55 AA 52 08 08
					15 00 00 40 00 00 02 E8 11
					15 00 00 00 00 00 02 E0 01
					/* DBV Remapping */
					39 00 00 00 00 00 06 F0 55 AA 52 08 09
					15 00 00 00 00 00 02 BC 01
					15 00 00 00 00 00 02 6F 25
					39 00 00 00 00 00 13 BC 01 9B 01 9B 01 9B 04 18 05 AC 06 F7 09 FF 0B FF 0D FF
					15 00 00 00 00 00 02 6F 37
					39 00 00 00 00 00 13 BC 11 54 12 A9 13 FE 1D EF 24 9F 2A B9 33 FD 37 FE 3B FE
					15 00 00 00 00 00 02 6F 49
					39 00 00 00 00 00 13 BC 01 9B 01 9B 01 9B 04 18 05 AC 06 F7 09 FF 0B FF 0D FF
					15 00 00 00 00 00 02 6F 5B
					39 00 00 00 00 00 13 BC 11 54 12 A9 13 FE 1D EF 24 9F 2A B9 33 FD 37 FE 3B FE
					/* ESD ERR Flag */
					39 00 00 00 00 00 06 F0 55 AA 52 08 00
					39 00 00 00 00 00 03 BE 47 45
					15 00 00 00 00 00 02 6F 05
					15 00 00 00 00 00 02 BE 08
					39 00 00 00 00 00 06 F0 55 AA 52 08 00
					15 00 00 00 00 00 02 6F 18
					15 00 00 00 00 00 02 B2 41
					/*  ESD error config */
					39 00 00 00 00 00 06 F0 55 AA 52 08 03
					39 00 00 00 00 00 04 C8 01 FF FB
					39 00 00 00 00 00 05 FF AA 55 A5 80
					15 00 00 00 00 00 02 6F 22
					15 00 00 00 00 00 02 FE 06
					/* APL Data scaling */
					39 00 00 00 00 00 06 F0 55 AA 52 08 00
					15 00 00 00 00 00 02 6F 78
					39 00 00 00 00 00 18 B0 11 00 2A 00 C2 01 DA 03 7C 05 B1 08 80 0B EE 0F FF 05 55 05 56 05 55
					15 00 00 00 00 00 02 6F 6F
					39 00 00 00 00 00 07 B0 02 D0 05 A0 02 D0
					39 00 00 00 00 00 06 F0 55 AA 52 08 08
					39 00 00 00 00 00 17 C1 8C FF CC FF FF CC FF FF CC FF FF EC FF 7F EE 7F 7F FF 7F FF 0E 7F
					15 00 00 00 00 00 02 6F 20
					39 00 00 00 00 00 04 C1 4F 00 FF
					15 00 00 00 00 00 02 6F 23
					39 00 00 00 00 00 15 C1 0C FF CC FF FF CC FF FF CC FF FF EC FF 7F EE 7F 7F CF 7F 0A
					/* Round ON */
					39 00 00 00 00 00 06 F0 55 AA 52 08 07
					15 00 00 00 00 00 02 C0 87
					/* OSC_Trim_On */
					39 00 00 00 00 00 06 F0 55 AA 52 08 01
					15 00 00 00 00 00 02 6F 2F
					15 00 00 00 00 00 02 C3 77
					/* OSC=125.2MHz, 1200Mbps */
					15 00 00 00 00 00 02 6F 00
					15 00 00 00 00 00 02 C3 DD
					15 00 00 00 00 00 02 6F 30
					15 00 00 00 00 00 02 C3 C0
					15 00 00 00 00 00 02 6F 0B
					39 00 00 00 00 00 04 C3 3F 3A 2F
					15 00 00 00 00 00 02 6F 11
					39 00 00 00 00 00 04 C3 3F 3A 2F
					15 00 00 00 00 00 02 6F 17
					39 00 00 00 00 00 04 C3 3F 3A 2F
					15 00 00 00 00 00 02 6F 1D
					39 00 00 00 00 00 04 C3 3F 3A 2F
					15 00 00 00 00 00 02 6F 23
					39 00 00 00 00 00 04 C3 3F 3A 2F
					15 00 00 00 00 00 02 6F 0E
					39 00 00 00 00 00 04 C3 3F 62 DE
					15 00 00 00 00 00 02 6F 14
					39 00 00 00 00 00 04 C3 3F 62 DE
					15 00 00 00 00 00 02 6F 1A
					39 00 00 00 00 00 04 C3 3F 62 DE
					15 00 00 00 00 00 02 6F 20
					39 00 00 00 00 00 04 C3 3F 62 DE
					15 00 00 00 00 00 02 6F 26
					39 00 00 00 00 00 04 C3 3F 62 DE
					15 00 00 00 00 00 02 6F 29
					39 00 00 00 00 00 04 C3 11 11 01
					15 00 00 00 00 00 02 6F 2C
					39 00 00 00 00 00 04 C3 00 00 00
					15 00 00 00 00 00 02 6F 31
					39 00 00 00 00 00 03 C3 AA 02
					15 00 00 00 00 00 02 6F 33
					39 00 00 00 00 00 03 C3 AA 02
					15 00 00 00 00 00 02 6F 04
					15 00 00 00 00 00 02 C3 E3
					15 00 00 00 00 00 02 6F 09
					15 00 00 00 00 00 02 C3 E4
					15 00 00 00 00 00 02 6F 01
					15 00 00 00 00 00 02 C3 29
					15 00 00 00 00 00 02 6F 06
					15 00 00 00 00 00 02 C3 29
					15 00 00 00 00 00 02 6F 02
					39 00 00 00 00 00 03 C3 02 70
					15 00 00 00 00 00 02 6F 08
					15 00 00 00 00 00 02 C3 70
					39 00 00 00 00 00 06 F0 55 AA 52 08 01
					15 00 00 00 00 00 02 EA 11
					15 00 00 00 00 00 02 6F 07
					39 00 00 00 00 00 03 EA 01 39
					15 00 00 00 00 00 02 6F 0B
					15 00 00 00 00 00 02 EA 11
					15 00 00 00 00 00 02 6F 12
					39 00 00 00 00 00 03 EA 01 AC
					15 00 00 00 00 00 02 6F 1A
					39 00 00 00 00 00 03 EA 01 39
					15 00 00 00 00 00 02 6F 1C
					39 00 00 00 00 00 03 EA 01 AC
					15 00 00 00 00 00 02 6F 04
					15 00 00 00 00 00 02 C3 EA
					15 00 00 00 00 00 02 6F 09
					15 00 00 00 00 00 02 C3 EA
					/* Sleep Out */
					05 00 00 00 78 00 02 11 00
					/* Display On */
					05 00 00 00 00 00 02 29 00
				];
				qcom,mdss-dsi-on-command-state = "dsi_lp_mode";

			};
		};
	};
};

&dsi_o11_42_02_0b_dsc_cmd {
	/* IRQF_ONESHOT | IRQF_TRIGGER_HEIGH */
	mi,esd-err-irq-gpio = <&tlmm 87 0x2004>;
	mi,panel-id = <0x004F3131 0x0042020A>;

	mi,flatmode-default-on-enabled;
	mi,need-fod-animal-in-normal-enabled;

	mi,doze-hbm-dbv-level = <252>;
	mi,doze-lbm-dbv-level = <25>;
	mi,max-brightness-clone = <16383>;

	mi,mdss-dsi-fac-bl-max-level = <5460>;
	mi,mdss-fac-brightness-max-level = <5460>;

	mi,thermal-dimming-flag;
	mi,disable-ic-dimming-flag;
	mi,panel-on-dimming-delay = <120>;
	mi,panel-3840pwm-dbv-threshold = <98>;

	mi,panel-build-id-read-needed;
	mi,panel-build-id-read-length = <1>;
	mi,mdss-dsi-panel-build-id-read-command = [06 01 00 01 00 00 01 DA];
	mi,mdss-dsi-panel-build-id-read-command-state = "dsi_hs_mode";

	mi,flatmode-status-check-enabled;
	mi,mdss-dsi-panel-flatmode-status-command = [
		06 01 00 01 00 00 01 5F
	];
	mi,mdss-dsi-panel-flatmode-status-command-state = "dsi_lp_mode";
	mi,mdss-dsi-panel-flatmode-status-read-length = <1>;
	mi,mdss-dsi-panel-flatmode-on-status-value = <0x00>;

};
